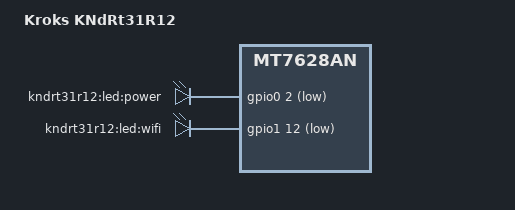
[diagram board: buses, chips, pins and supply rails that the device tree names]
/dts-v1/;

#include "mt7628an_kroks_1eth-1mm-inj.dtsi"

/ {
	compatible = "kroks,kndrt31r12", "mediatek,mt7628an-soc";
	model = "Kroks KNdRt31R12";

	aliases {
		led-boot = &led_power;
		led-failsafe = &led_power;
		led-running = &led_power;
		led-upgrade = &led_power;
	};

	leds {
		compatible = "gpio-leds";

		led_power: power {
			label = "kndrt31r12:led:power";
			gpios = <&gpio0 2 GPIO_ACTIVE_LOW>;
		};

		wifi {
			label = "kndrt31r12:led:wifi";
			gpios = <&gpio1 12 GPIO_ACTIVE_LOW>;
			linux,default-trigger = "phy0tpt";
		};
	};
};
